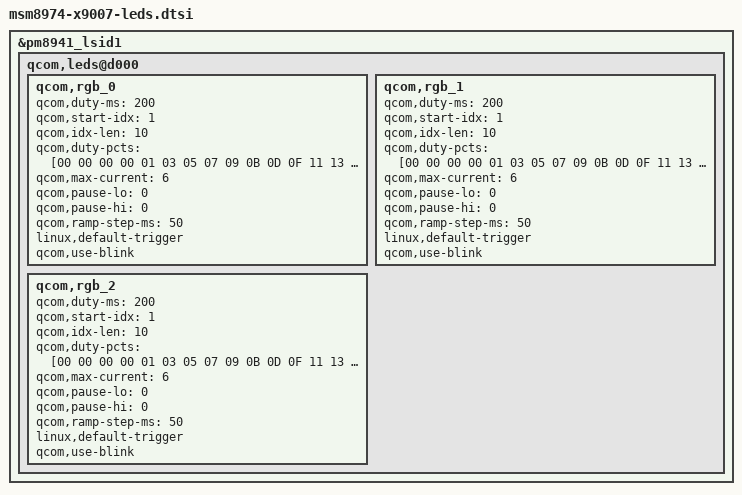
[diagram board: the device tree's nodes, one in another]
/* Copyright (c) 2012-2013, The Linux Foundation. All rights reserved.
 *
 * This program is free software; you can redistribute it and/or modify
 * it under the terms of the GNU General Public License version 2 and
 * only version 2 as published by the Free Software Foundation.
 *
 * This program is distributed in the hope that it will be useful,
 * but WITHOUT ANY WARRANTY; without even the implied warranty of
 * MERCHANTABILITY or FITNESS FOR A PARTICULAR PURPOSE.  See the
 * GNU General Public License for more details.
 */

&pm8941_lsid1 {
	qcom,leds@d000 {
		qcom,rgb_0 {
			qcom,duty-ms = <200>;
			qcom,start-idx = <1>;
			qcom,idx-len = <10>;
			qcom,duty-pcts = [00 00 00 00 01 03 05 07 09 0B 0D 0F
				11 13 16 19 1C 1F 23 26 29 2B 2E
				32 39 42 4B 57 64 64
				64 64 57 4B 42 39 32
				2E 2B 29 26 23 1F 1C 19 16 13 11
				0F 0D 0B 09 07 05 03 01 00 00 00 00];
			qcom,max-current = <6>;
			qcom,pause-lo = <0>;
			qcom,pause-hi = <0>;
			qcom,ramp-step-ms = <50>;
			linux,default-trigger;
			qcom,use-blink;
		};

		qcom,rgb_1 {
			qcom,duty-ms = <200>;
			qcom,start-idx = <1>;
			qcom,idx-len = <10>;
			qcom,duty-pcts = [00 00 00 00 01 03 05 07 09 0B 0D 0F
				11 13 16 19 1C 1F 23 26 29 2B 2E
				32 39 42 4B 57 64 64
				64 64 57 4B 42 39 32
				2E 2B 29 26 23 1F 1C 19 16 13 11
				0F 0D 0B 09 07 05 03 01 00 00 00 00];
			qcom,max-current = <6>;
			qcom,pause-lo = <0>;
			qcom,pause-hi = <0>;
			qcom,ramp-step-ms = <50>;
			linux,default-trigger;
			qcom,use-blink;
		};

		qcom,rgb_2 {
			qcom,duty-ms = <200>;
			qcom,start-idx = <1>;
			qcom,idx-len = <10>;
			qcom,duty-pcts = [00 00 00 00 01 03 05 07 09 0B 0D 0F
				11 13 16 19 1C 1F 23 26 29 2B 2E
				32 39 42 4B 57 64 64
				64 64 57 4B 42 39 32
				2E 2B 29 26 23 1F 1C 19 16 13 11
				0F 0D 0B 09 07 05 03 01 00 00 00 00];
			qcom,max-current = <6>;
			qcom,pause-lo = <0>;
			qcom,pause-hi = <0>;
			qcom,ramp-step-ms = <50>;
			linux,default-trigger;
			qcom,use-blink;
		};
	};
};
